# cslr_usb register map
Vendor: Texas Instruments
Peripheral module from a debugger description file (folder C5517).
Address unit: 16 bits
Registers are 16-bit, access not given, reset 0x0 unless marked. A register's access mark holds for its fields unless they carry their own. Offsets are as the file gives them; lines under a group give offsets from that group; [hi:lo] are bit positions; {n}, {i} and the like mark numbered series; 'fields as' and 'values as' point back to an identical list; <NAME> marks a mode.

## USB — USB2.0 OTG Controller
0x00 REVID1 ro reset 0x800 — Revision Identification Register 1
  [15:0] REVLSB — Lower-significant bits of the revision.
0x01 REVID2 ro reset 0x4EA1 — Revision Identification Register 2
  [15:0] REVMSB — Most-significant bits of the revision.
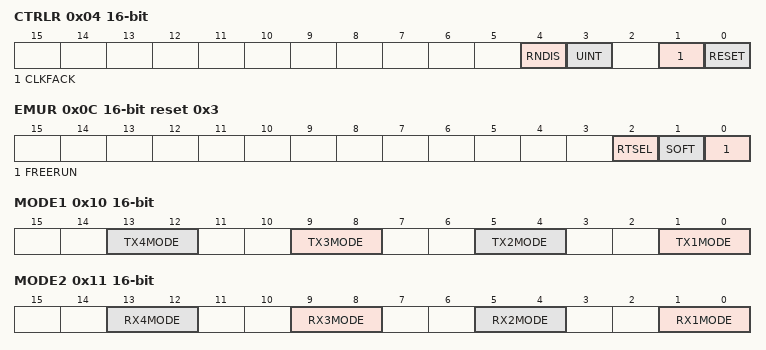
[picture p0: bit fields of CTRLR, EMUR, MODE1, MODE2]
0x04 CTRLR — Control Register
  [4] RNDIS rw — Global RNDIS mode enable for all endpoints.
    0=DISABLED (Global RNDIS mode is disabled.); 1=ENABLED (Global RNDIS mode is enabled.)
  [3] UINT rw — USB non-PDR interrupt handler enable.
    0=DISABLED (PDR interrupt handler is enabled.); 1=ENABLED (PDR interrupt handler is disabled.)
  [1] CLKFACK rw — Clock stop fast ACK enable.
    0=DISABLED (Clock stop fast ACK is disabled.); 1=ENABLED (Clock stop fast ACK is enabled.)
  [0] RESET rw — Soft reset.
    0=NONE (No effect.); 1=START (Writing a 1 starts a module reset.)
0x08 STATR — Status Register
  [0] DRVVBUS ro — Current DRVVBUS value
    0=LOGIC0 (DRVVBUS value is logic 0.); 1=LOGIC1 (DRVVBUS value is logic 1.)
0x0C EMUR reset 0x3 — Emulation Register
  [2] RTSEL rw — Real-time Enable
    0=ENABLE; 1=NOEFFECT
  [1] SOFT rw — Soft Stop Enable
    0=NOEFFECT; 1=ENABLE (Soft stop enable)
  [0] FREERUN rw — Free Run Enable
    0=NOEFFECT; 1=ENABLE (Free run enable)
0x10 MODE1 — Mode Register 1
  [4n-3:4n-4] TX{n}MODE rw (n=1..4) — Transmit endpoint {n} mode control.
    0=TRANS (Transparent mode on Transmit endpoint {n}); 1=RNDIS (RNDIS mode on Transmit endpoint {n}); 2=CDC (CDC mode on Transmit endpoint {n}); 3=GENRNDIS (Generic RNDIS mode on Transmit endpoint {n})
0x11 MODE2 — Mode Register 2
  [4n-3:4n-4] RX{n}MODE rw (n=1..4) — Receive endpoint {n} mode control
    0=TRANS (Transparent mode on Receive endpoint {n}); 1=RNDIS (RNDIS mode on Receive endpoint {n}); 2=CDC (CDC mode on Receive endpoint {n}); 3=GENRNDIS (Generic RNDIS mode on Receive endpoint {n})
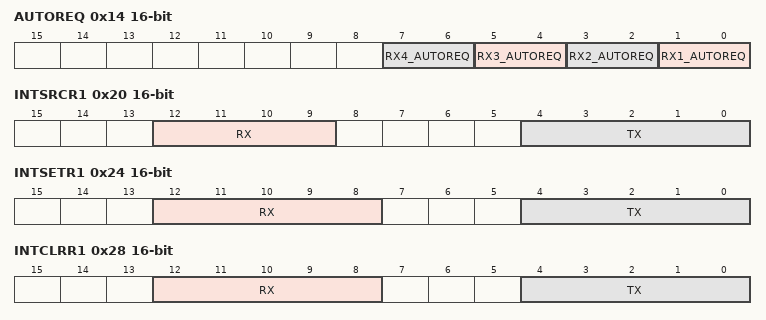
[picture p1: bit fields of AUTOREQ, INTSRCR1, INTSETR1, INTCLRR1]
0x14 AUTOREQ — Auto Request Register
  [all] fields
    0=NOAUTO (No auto request.); 1=AUTO (Auto request on all but EOP); 2=RSV (Reserved); 3=AUTOALWYS (Auto request always)
  [2n-1:2n-2] RX{n}_AUTOREQ rw (n=1..4) — Receive endpoint {n} auto request enable
0x18 SPRFIXTIME1 rw reset 0xDE80 — SRP Fix Time Register 1
  [15:0] SRPFIXTIME — SRP fix maximum time in 60 MHz cycles. Default is 700 ms (280 DE80h). Least-significant bits.
0x19 SPRFIXTIME2 rw reset 0x280 — SRP Fix Time Register 2
  [15:0] SRPFIXTIME — SRP fix maximum time in 60 MHz cycles. Default is 700 ms (280 DE80h). Most-significant bits.
0x1C TEARDOWN1 — Teardown Register 1
  [4:1] RX_TDOWN ro — RX Endpoint Teardown. Write '1' to corresponding bit to set. Read as '0'.
    0=DISABLE; 1=ENABLE
0x1D TEARDOWN2 — Teardown Register 2
  [4:1] TX_TDOWN ro — TX Endpoint Teardown. Write '1' to corresponding bit to set. Read as '0'.
    0=DISABLE; 1=ENABLE
0x20 INTSRCR1 — USB Interrupt Source Register 1
  [12:9] RX ro — RX endpoint interrupt sources Generated by the USB core (not the DMA)
  [4:0] TX ro — TX endpoint interrupt sources Generated by the USB core (not the DMA)
0x21 INTSRCR2 — USB Interrupt Source Register 2
  [8:0] USB ro — USB interrupt sources Generated by the USB core (not the DMA)
0x24 INTSETR1 — USB Interrupt Source Set Register 1
  [12:8] RX wo — Write a 1 to set equivalent RX endpoint interrupt source Allows the USB interrupt sources to be manually triggered
  [4:0] TX wo — Write a 1 to set equivalent TX endpoint interrupt source Allows the USB interrupt sources to be manually triggered
0x25 INTSETR2 — USB Interrupt Source Set Register 2
  [8:0] USB wo — Write a 1 to set equivalent USB interrupt source Allows the USB interrupt sources to be manually triggered
0x28 INTCLRR1 — USB Interrupt Source Clear Register 1
  [12:8] RX wo — Write a 1 to clear equivalent RX endpoint interrupt source Allows the CPU to acknowledge an interrupt source and turn it off
  [4:0] TX wo — Write a 1 to clear equivalent TX endpoint interrupt source Allows the CPU to acknowledge an interrupt source and turn it off
0x29 INTCLRR2 — USB Interrupt Source Clear Register 2
  [8:0] USB wo — Write a 1 to clear equivalent USB interrupt source Allows the CPU to acknowledge an interrupt source and turn it off
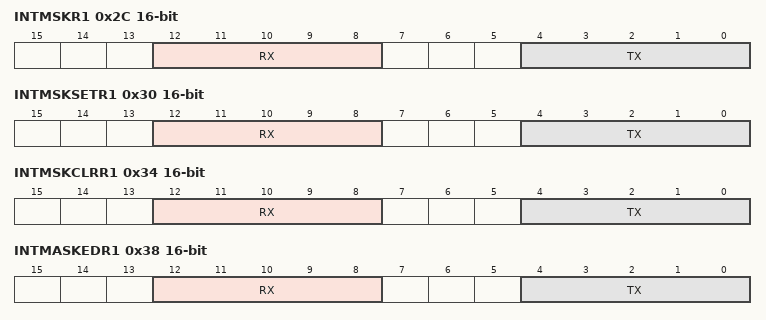
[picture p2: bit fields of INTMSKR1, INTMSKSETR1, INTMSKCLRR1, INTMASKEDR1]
0x2C INTMSKR1 — USB Interrupt Mask Register 1
  [12:8] RX ro — RX endpoint interrupt source masks Contains the masks of the interrupt sources generated by the USB core (not the DMA). These masks are used to enable or disable interrupt sources appearing as masked interrupts
  [4:0] TX ro — TX endpoint interrupt source masks Contains the masks of the interrupt sources generated by the USB core (not the DMA). These masks are used to enable or disable interrupt sources appearing as masked interrupts
0x2D INTMSKR2 — USB Interrupt Mask Register 2
  [8:0] USB ro — USB interrupt source masks Contains the masks of the interrupt sources generated by the USB core (not the DMA). These masks are used to enable or disable interrupt sources appearing as masked interrupts
0x30 INTMSKSETR1 — USB Interrupt Mask Set Register 1
  [12:8] RX wo — Write a 1 to set equivalent RX endpoint interrupt mask Allows the USB interrupt masks to be individually enabled
  [4:0] TX wo — Write a 1 to set equivalent TX endpoint interrupt mask Allows the USB interrupt masks to be individually enabled
0x31 INTMSKSETR2 — USB Interrupt Mask Set Register 2
  [8:0] USB wo — Write a 1 to set equivalent USB interrupt mask Allows the USB interrupt masks to be individually enabled
0x34 INTMSKCLRR1 — USB Interrupt Mask Clear Register 1
  [12:8] RX wo — Write a 1 to clear equivalent RX endpoint interrupt mask Allows the USB interrupt masks to be individually disabled
  [4:0] TX wo — Write a 1 to clear equivalent TX endpoint interrupt mask Allows the USB interrupt masks to be individually disabled
0x35 INTMSKCLRR2 — USB Interrupt Mask Clear Register 2
  [8:0] USB wo — Write a 1 to clear equivalent USB interrupt mask Allows the USB interrupt masks to be individually disabled
0x38 INTMASKEDR1 — USB Interrupt Source Masked Register 1
  [12:8] RX ro — RX endpoint interrupt sources masked Contains the status of the interrupt sources generated by the USB core masked by the USB Interrupt Mask Register values
  [4:0] TX ro — TX endpoint interrupt sources masked Contains the status of the interrupt sources generated by the USB core masked by the USB Interrupt Mask Register values
0x39 INTMASKEDR2 — USB Interrupt Source Masked Register 2
  [8:0] USB ro — USB interrupt sources masked Contains the status of the interrupt sources generated by the USB core masked by the USB Interrupt Mask Register values
0x3C EOIR — USB End of Interrupt Register
  [7:0] EOI_VECTOR rw
0x40 INTVECTR1 ro — USB Interrupt Vector Register 1
  [15:0] VECTOR — Input Interrupt Vector. Least significant bits.
0x41 INTVECTR2 ro — USB Interrupt Vector Register 2
  [15:0] VECTOR — Input Interrupt Vector. Most-significant bits.
{0x4C+4i} GREP{i}SZR1 ro (i=1..4) — Generic RNDIS EP{i} Size Register 1
  [15:0] SIZE — Generic RNDIS packet size. Least-significant bits.
{0x4D+4i} GREP{i}SZR2 (i=1..4) — Generic RNDIS EP{i} Size Register 2
  [0] SIZE ro — Generic RNDIS packet size. Most-significant bit.
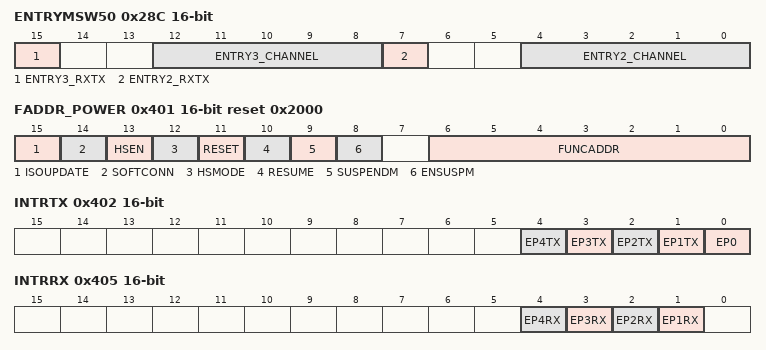
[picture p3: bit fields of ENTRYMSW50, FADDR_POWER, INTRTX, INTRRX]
0x28C ENTRYMSW50 — CDMA Scheduler Table Word Register MSW
  [15] ENTRY3_RXTX wo — This entry is for a transmit or a receive channel.
    0=XMTCH (Transmit channel); 1=RCVCH (Receive channel)
  [12:8] ENTRY3_CHANNEL wo — Indicates the channel number that is to be given an opportunity to transfer data. If this is a transmit entry, the DMA will be presented with a scheduling credit for that exact transmit channel. If this is a receive entry, the DMA will be presented with a scheduling credit for the receive FIFO that is associated with this channel. For receive FIFOs which carry traffic for more than one receive DMA channel, the exact channel number that is given in the receive credit will actually be the channel number which is currently on the head element of that Rx FIFO, which is not necessarily the channel number given in the scheduler table entry.
  [7] ENTRY2_RXTX wo — This entry is for a transmit or a receive channel.
    0=XMTCH (Transmit channel); 1=RCVCH (Receive channel)
  [4:0] ENTRY2_CHANNEL wo — Indicates the channel number that is to be given an opportunity to transfer data. If this is a transmit entry, the DMA will be presented with a scheduling credit for that exact transmit channel. If this is a receive entry, the DMA will be presented with a scheduling credit for the receive FIFO that is associated with this channel. For receive FIFOs which carry traffic for more than one receive DMA channel, the exact channel number that is given in the receive credit will actually be the channel number which is currently on the head element of that Rx FIFO, which is not necessarily the channel number given in the scheduler table entry.
0x401 FADDR_POWER reset 0x2000 — Function Address Register and Power Management Register
  [15] ISOUPDATE rw — When set, the USB controller will wait for an SOF token from the time TxPktRdy is set before sending the packet. If an IN token is received before an SOF token, then a zero length data packet will be sent Note: Only valid in Peripheral Mode. Also, this bi
  [14] SOFTCONN rw — If Soft Connect/Disconnect feature is enabled, then the USB D+/D- lines are enabled when this bit is set and tri-stated when this bit is cleared Note: Only valid in Peripheral Mode
  [13] HSEN rw — When set, the USB controller will negotiate for High-speed mode when the device is reset by the hub. If not set, the device will only operate in Full-speed mode
  [12] HSMODE ro — This bit is set when the USB contoller has successfully negotiated for High-speed mode
  [11] RESET rw — This bit is set when Reset signaling is present on the bus Note: This bit is Read/Write in Host Mode but Read-Only in Peripheral Mode
  [10] RESUME rw — Set to generate Resume signaling when the controller is in Suspend mode. The bit should be cleared after 10 ms (a maximum of 15 ms) to end Resume signaling. In Host mode, this bit is also automatically set when Resume signaling from the target is detected
  [9] SUSPENDM rw — In Host mode, this bit should be set to enter Suspend mode. In Peripheral mode, this bit is set on entry into Suspend mode. It is cleared when the interrupt register is read, or the RESUME bit is set
  [8] ENSUSPM rw — Set to enable the SUSPENDM output
  [6:0] FUNCADDR rw — 7_bit address of the peripheral part of the transaction. When used in Peripheral mode, this register should be written with the address received through a SET_ADDRESS command, which will then be used for decoding the function address in subsequent token packets. When used in Host mode, this register should be set to the value sent in a SET_ADDRESS command during device enumeration as the address for the peripheral device.
0x402 INTRTX — Interrupt Register for Endpoint 0 Plus Transmit Endpoints 1 to 4
  [n] EP{n}TX ro (n=1..4) — Tx Endpoint {n} interrupt active
  [0] EP0 ro — Endpoint 0 interrupt active
0x405 INTRRX — Interrupt Register for Receive Endpoints 1 to 4
  [n] EP{n}RX ro (n=1..4) — Rx Endpoint {n} interrupt active
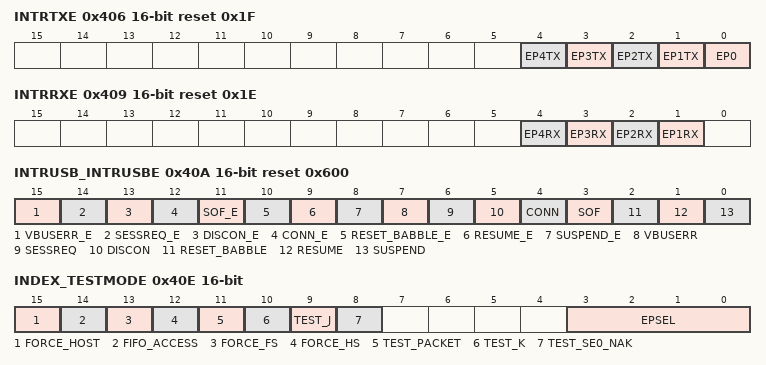
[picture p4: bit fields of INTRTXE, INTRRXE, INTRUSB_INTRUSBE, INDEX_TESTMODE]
0x406 INTRTXE reset 0x1F — Interrupt Enable Register for INTRTX
  [n] EP{n}TX rw (n=1..4) — Tx Endpoint {n} interrupt enable
  [0] EP0 rw — Endpoint 0 interrupt enable
0x409 INTRRXE reset 0x1E — Interrupt Enable Register for INTRRX
  [n] EP{n}RX rw (n=1..4) — Rx Endpoint {n} interrupt enable
0x40A INTRUSB_INTRUSBE access per field reset 0x600 — Interrupt Register for Common USB Interrupts and Interrupt Enable Register for INTRUSB
  [15] VBUSERR_E rw — Vbus error interrupt enable
  [14] SESSREQ_E rw — Session request interrupt enable
  [13] DISCON_E rw — Disconnect interrupt enable
  [12] CONN_E rw — Connect interrupt enable
  [11] SOF_E rw — Start of frame interrupt enable
  [10] RESET_BABBLE_E rw — Reset interrupt enable
  [9] RESUME_E rw — Resume interrupt enable
  [8] SUSPEND_E rw — Suspend interrupt enable
  [7] VBUSERR ro — Set when VBus drops below the VBus Valid threshold during a session Only valid when USB controller is A device All active interrupts will be cleared when this register is read
  [6] SESSREQ ro — Set when Session Request signaling has been detected Only valid when USB controller is A device
  [5] DISCON ro — Set in Host mode when a device disconnect is detected Set in Peripheral mode when a session ends
  [4] CONN ro — Set when a device connection is detected Only valid in Host mode
  [3] SOF ro — Set when a new frame starts
  [2] RESET_BABBLE ro — Set in Peripheral mode when Reset signaling is detected on the bus Set in Host mode when babble is detected
  [1] RESUME ro — Set when Resume signaling is detected on the bus while the USB controller is in Suspend mode
  [0] SUSPEND ro — Set when Suspend signaling is detected on the bus Only valid in Peripheral mode
0x40D FRAME — Frame Number Register
  [10:0] FRAMENUMBER ro — Last received frame number
0x40E INDEX_TESTMODE — Index Register for Selecting the Endpoint Status and Control Registers and Register to Enable the USB 2.0 Test Modes
  [15] FORCE_HOST rw — Set this bit to forcibly put the USB controller into Host mode when SESSION bit is set, regardless of whether it is connected to any peripheral. The controller remains in Host mode until the Session bit is cleared, even if a device is disconnected. And if the FORCE_HOST but remains set, it will re-enter Host mode next time the SESSION bit is set. The operating speed is determined using the FORCE_HS and FORCE_FS bits
  [14] FIFO_ACCESS wo — Set this bit to transfer the packet in EP0 Tx FIFO to EP0 Rx FIFO. It is cleared automatically
  [13] FORCE_FS rw — Set this bit to force the USB controller into Full-speed mode when it receives a USB reset
  [12] FORCE_HS rw — Set this bit to force the USB controller into High-speed mode when it receives a USB reset
  [11] TEST_PACKET rw — Set this bit to enter the Test_Packet test mode. In this mode, the USB controller repetitively transmits on the bus a 53-byte test packet, the form of which is defined in the Universal Serial Bus Specification Revision 2.0 Note: The test packet has a fixed format and must be loaded into the Endpoint 0 FIFO before the test mode is entered
  [10] TEST_K rw — Set this bit to enter the Test_K test mode. In this mode, the USB controller transmits a continuous K on the bus
  [9] TEST_J rw — Set this bit to enter the Test_J test mode. In this mode, the USB controller transmits a continuous J on the bus
  [8] TEST_SE0_NAK rw — Set this bit to enter the Test_SE0_NAK test mode. In this mode, the USB controller remains in High-speed mode but responds to any valid IN token with a NAK
  [3:0] EPSEL rw — Each Tx endpoint and each Rx endpoint have their own set of control/status registers. EPSEL determines which endpoint control/status registers are accessed Before accessing an endpoint s control/status registers, the endpoint number should be written to the Index register to ensure that the correct control/status registers appear in the memory map
0x411 TXMAXP_INDX — Maximum packet size for peripheral/host Tx endpoint (Index register set to select Endpoints 1 - 4 only)
  [10:0] MAXPAYLOAD rw — The maximum payload transmitted in a single transaction The value set can be up to 1024 bytes but is subject to the constraints placed by the USB Specification on packet sizes for Bulk, Interrupt and Isochronous transfers in Full-speed and High-speed operations The value written to this register should match the wMaxPacketSize field of the Standard Endpoint Descriptor for the associated endpoint. A mismatch could cause unexpected results
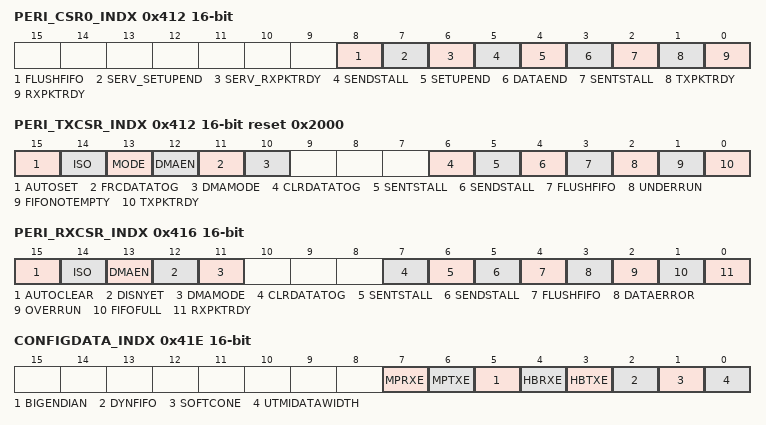
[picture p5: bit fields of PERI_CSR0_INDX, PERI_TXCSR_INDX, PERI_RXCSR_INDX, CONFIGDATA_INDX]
0x412 PERI_CSR0_INDX — Control Status register for Endpoint 0 in Peripheral mode. (Index register set to select Endpoint 0)
  [8] FLUSHFIFO wo — Set this bit to flush the next packet to be transmitted/read from the Endpoint 0 FIFO. The FIFO pointer is reset and the TXPKTRDY/RXPKTRDY bit (below) is cleared Note: FLUSHFIFO has no effect unless TXPKTRDY/RXPKTRDY is set
  [7] SERV_SETUPEND wo — Set this bit to clear the SETUPEND bit. It is cleared automatically
  [6] SERV_RXPKTRDY wo — Set this bit to clear the RXPKTRDY bit. It is cleared automatically
  [5] SENDSTALL wo — Set this bit to terminate the current transaction. The STALL handshake will be transmitted and then this bit will be cleared automatically
  [4] SETUPEND ro — This bit will be set when a control transaction ends before the DATAEND bit has been set. An interrupt will be generated and the FIFO flushed at this time. The bit is cleared by the user writing a 1 to the SERV_SETUPEND bit
  [3] DATAEND wo — Set this bit 1. When setting TXPKTRDY for the last data packet 2. When clearing RXPKTRDY after unloading the last data packet 3. When setting TXPKTRDY for a zero length data packet It is cleared automatically
  [2] SENTSTALL rw — This bit is set when a STALL handshake is transmitted. This bit should be cleared by the user
  [1] TXPKTRDY rw — Set this bit after loading a data packet into the FIFO. It is cleared automatically when the data packet has been transmitted. An interrupt is generated (if enabled) when the bit is cleared
  [0] RXPKTRDY ro — This bit is set when a data packet has been received. An interrupt is generated when this bit is set. This bit is cleared by setting the SERV_RXPKTRDY bit
0x412 PERI_TXCSR_INDX reset 0x2000 — Control Status register for peripheral Tx endpoint. (Index register set to select Endpoints 1 4)
  [15] AUTOSET rw — When this bit is set, TXPKTRDY will be automatically set when data of the maximum packet size (value in TXMAXP is loaded into the Tx FIFO. If a packet of less than the maximum packet size is loaded, then TXPKTRDY will have to be set manually. TXPKTRDY will also be automatically set when the first of two packets in the Tx FIFO has been sent and the second packet is the maximum packet size
  [14] ISO rw — Set this bit to enable the Tx endpoint for Isochronous transfers, and clear it to enable the Tx endpoint for Bulk or Interrupt transfers
  [13] MODE rw — Set this bit to enable the endpoint direction as Tx, and clear the bit to enable it as Rx Note: This bit only has any effect where the same endpoint FIFO is used for both Tx and Rx transactions
  [12] DMAEN rw — Set this bit to enable the DMA request for the Tx endpoint
  [11] FRCDATATOG rw — Set this bit to force the endpoint data toggle to switch and the data packet to be cleared from the FIFO, regardless of whether an ACK was received. This can be used by Interrupt Tx endpoints that are used to communicate rate feedback for Isochronous endpoints
  [10] DMAMODE rw — This bit should always be 0
  [6] CLRDATATOG wo — Write a 1 to this bit to reset the endpoint data toggle to 0
  [5] SENTSTALL rw — This bit is set automatically when a STALL handshake is transmitted. The FIFO is flushed and the TXPKTRDY bit is cleared (see below). The user should clear this bit
  [4] SENDSTALL rw — Write a 1 to this bit to issue a STALL handshake to an IN token. Clear this bit to terminate the stall condition Note: This bit has no effect where the endpoint is being used for Isochronous transfers
  [3] FLUSHFIFO wo — Write a 1 to this bit to flush the next packet to be transmitted from the endpoint Tx FIFO. The FIFO pointer is reset and the TXPKTRDY bit (below) is cleared. Note: FlushFIFO has no effect unless TXPKTRDY is set. Also note that, if the FIFO is double-buffered, FlushFIFO may need to be set twice to completely clear the FIFO
  [2] UNDERRUN rw — This bit is set automatically if an IN token is received when TXPKTRDY is not set. The user should clear this bit
  [1] FIFONOTEMPTY rw — This bit is set when there is at least 1 packet in the Tx FIFO. The user should clear this bit
  [0] TXPKTRDY rw — Set this bit after loading a data packet into the FIFO. It is cleared automatically when a data packet has been transmitted. An interrupt is generated (if enabled) when the bit is cleared
0x415 RXMAXP_INDX — Maximum packet size for peripheral/host Rx endpoint (Index register set to select Endpoints 1 - 4 only)
  [10:0] MAXPAYLOAD rw — Defines the maximum amount of data that can be transferred through the selected Rx endpoint in a single frame / microframe (High-speed transfers) The value set can be up to 1024 bytes but is subject to the constraints placed by the USB Specification on packet sizes for Bulk, Interrupt and Isochronous transfers in Full-speed and High-speed operations The value written to this register should match the wMaxPacketSize field of the Standard Endpoint Descriptor for the associated endpoint. A mismatch could cause unexpected results
0x416 PERI_RXCSR_INDX — Control Status register for peripheral Rx endpoint. (Index register set to select Endpoints 1 4)
  [15] AUTOCLEAR rw — When this bit is set, the RXPKTRDY bit will be automatically cleared when a packet of RXMAXP bytes has been unloaded from the Rx FIFO. When packets of less than the maximum packet size are unloaded, RXPKTRDY will have to be cleared manually
  [14] ISO rw — Set this bit to enable the Rx endpoint for Isochronous transfers, and clear it to enable the Rx endpoint for Bulk/Interrupt transfers
  [13] DMAEN rw — Set this bit to enable the DMA request for the Rx endpoints
  [12] DISNYET rw — Set this bit to disable the sending of NYET handshakes. When set, all successfully received Rx packets are ACK'd including at the point at which the FIFO becomes full Note: This bit only has any effect in High-speed mode, in which mode it should be set for all Interrupt endpoints
  [11] DMAMODE rw — This bit should always be 0
  [7] CLRDATATOG wo — Write a 1 to this bit to reset the endpoint data toggle to 0
  [6] SENTSTALL rw — This bit is set when a STALL handshake is transmitted. The FIFO is flushed and the TXPKTRDY bit is cleared (see below). The user should clear this bit
  [5] SENDSTALL rw — Write a 1 to this bit to issue a STALL handshake Clear this bit to terminate the stall condition Note: This bit has no effect where the endpoint is being used for Isochronous transfers
  [4] FLUSHFIFO wo — Write a 1 to this bit to flush the next packet to be read from the endpoint Rx FIFO. The FIFO pointer is reset and the RXPKTRDY bit (below) is cleared Note: FLUSHFIFO has no effect unless RXPKTRDY is set. Also note that, if the FIFO is double-buffered, FLUSHFIFO may need to be set twice to completely clear the FIFO
  [3] DATAERROR ro — This bit is set when RXPKTRDY is set if the data packet has a CRC or bit-stuff error. It is cleared when RXPKTRDY is cleared Note: This bit is only valid when the endpoint is operating in ISO mode. In Bulk mode, it always returns zero.
  [2] OVERRUN rw — This bit is set if an OUT packet cannot be loaded into the Rx FIFO. The user should clear this bit Note: This bit is only valid when the endpoint is operating in ISO mode. In Bulk mode, it always returns zero
  [1] FIFOFULL ro — This bit is set when no more packets can be loaded into the Rx FIFO
  [0] RXPKTRDY rw — This bit is set when a data packet has been received. The user should clear this bit when the packet has been unloaded from the Rx FIFO. An interrupt is generated when the bit is set
0x419 COUNT0_INDX — Number of received bytes in Endpoint 0 FIFO. (Index register set to select Endpoint 0)
  [6:0] EP0RXCOUNT ro — Indicates the number of received data bytes in the Endpoint 0 FIFO The value returned changes as the contents of the FIFO change and is only valid while RXPKTRDY of PERI_CSR0 or HOST_CSR0 is set
0x419 RXCOUNT_INDX — Number of bytes in host Rx endpoint FIFO. (Index register set to select Endpoints 1 - 4)
  [12:0] EPRXCOUNT ro — Holds the number of received data bytes in the packet in the Rx FIFO The value returned changes as the contents of the FIFO change and is only valid while RXPKTRDY of PERI_RXCSR or HOST_RXCSR is set
0x41E CONFIGDATA_INDX — Returns details of core configuration (Index register set to select Endpoint 0)
  [7] MPRXE — Indicates automatic amalgamation of bulk packets. (access N)
    0=NOAUTO (Automatic amalgamation of bulk packets is not selected.); 1=AUTO (Automatic amalgamation of bulk packets is selected.)
  [6] MPTXE ro — Indicates automatic splitting of bulk packets.
    0=NOAUTO (Automatic splitting of bulk packets is not selected.); 1=AUTO (Automatic splitting of bulk packets is selected.)
  [5] BIGENDIAN ro — Indicates endian ordering.
    0=LITTLE (Little-endian ordering is selected.); 1=BIG (Big-endian ordering is selected.)
  [4] HBRXE ro — Indicates high-bandwidth Rx ISO endpoint support.
    0=NOHIGHBW (High-bandwidth Rx ISO endpoint support is not selected.); 1=HIGHBW (High-bandwidth Rx ISO endpoint support is selected.)
  [3] HBTXE ro — Indicates high-bandwidth Tx ISO endpoint support.
    0=NOHIGHBW (High-bandwidth Tx ISO endpoint support is not selected.); 1=HIGHBW (High-bandwidth Tx ISO endpoint support is Selected.)
  [2] DYNFIFO ro — Indicates dynamic FIFO sizing.
    0=NODYMFIFO (Dynamic FIFO sizing option is not selected.); 1=DYMFIFO (Dynamic FIFO sizing option is selected.)
  [1] SOFTCONE ro — Indicates soft connect/disconnect.
    0=NOSFTCON (Soft connect/disconnect option is not selected); 1=SFTCON (Soft connect/disconnect option is selected)
  [0] UTMIDATAWIDTH ro — Indicates selected UTMI data width.
    0=EIGHT (8 bits); 1=SIXTEEN (16 bits)
{0x421+4i} FIFO{i}R1 rw (i=0..4) — Transmit and Receive FIFO Register 1 for Endpoint {i}
  [15:0] DATA — Writing to these addresses loads data into the Transmit FIFO for the corresponding endpoint. Reading from these addresses unloads data from the Receive FIFO for the corresponding endpoint. Least-significant bits.
{0x422+4i} FIFO{i}R2 rw (i=0..4) — Transmit and Receive FIFO Register 2 for Endpoint {i}
  [15:0] DATA — Writing to these addresses loads data into the Transmit FIFO for the corresponding endpoint. Reading from these addresses unloads data from the Receive FIFO for the corresponding endpoint. Most-significant bits.
0x461 DEVCTL — OTG Device Control Register
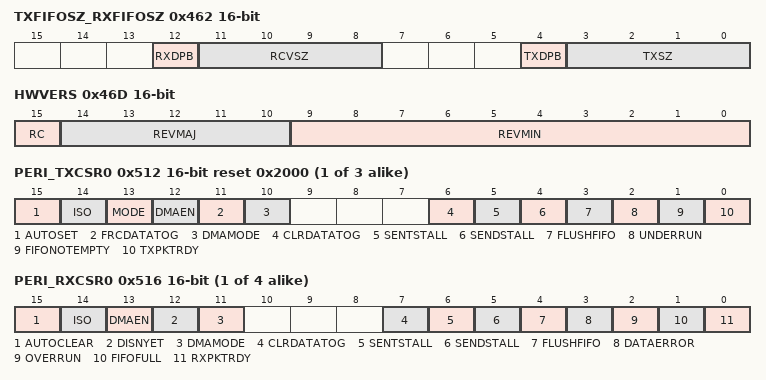
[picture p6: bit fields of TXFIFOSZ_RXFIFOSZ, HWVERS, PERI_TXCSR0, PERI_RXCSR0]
0x462 TXFIFOSZ_RXFIFOSZ — Tx RX Endpoint FIFO Size(Index register set to select Endpoints 1 - 4 only)
  [12] RXDPB rw — Double packet buffering enable
    0=SINGLE (Single packet buffering is supported); 1=DOUBLE (Double packet buffering is enabled)
  [11:8] RCVSZ ro — Maximum packet size to be allowed(before any splitting within the FIFO of Bulk packets prior to transmission) If m = SZ[3:0], the FIFO size is calculated as 2(m+3) for single packet buffering and 2(m+4) for dual packet buffering
  [4] TXDPB rw — Double packet buffering enable
    values as RXDPB
  [3:0] TXSZ ro — Maximum packet size to be allowed(before any splitting within the FIFO of Bulk packets prior to transmission) If m = SZ[3:0], the FIFO size is calculated as 2(m+3) for single packet buffering and 2(m+4) for dual packet buffering
0x465 TXFIFOADDR — Tx Endpoint FIFO Address(Index register set to select Endpoints 1 - 4 only)
  [12:0] ADDR rw — Start Address of endpoint FIFO in units of 8 bytes If m = ADDR[12:0] then the start address is 8*m
0x466 RXFIFOADDR — Rx Endpoint FIFO Address(Index register set to select Endpoints 1 - 4 only)
  fields as TXFIFOADDR
0x46D HWVERS — The hardware version register (HWVERS) contains the RTL major and minor version numbers for the USB 2.0 OTG controller module. The RTL version number is REVMAJ.REVMIN.
  [15] RC — Set to 1 if RTL is used from a Release Candidate, rather than from a full release of the core. (access N)
  [14:10] REVMAJ ro — Major version of RTL. Range is 0-31.
  [9:0] REVMIN ro — Minor version of RTL. Range is 0-999.
{0x511+0x10*i} TXMAXP{i} (i=0..2) — Maximum packet size for peripheral/host Tx endpoint
  fields as TXMAXP_INDX
{0x512+0x10*i} PERI_TXCSR{i} reset 0x2000 (i=0..2) — Control Status register for peripheral Tx endpoint. (Index register set to select Endpoints 1 4)
  fields as PERI_TXCSR_INDX
{0x515+0x10*i} RXMAXP{i} (i=0..3) — Maximum packet size for peripheral/host Rx endpoint
  fields as RXMAXP_INDX
{0x516+0x10*i} PERI_RXCSR{i} (i=0..3) — Control Status register for peripheral Rx endpoint.
  fields as PERI_RXCSR_INDX
{0x519+0x10*i} RXCOUNT{i} (i=0..3) — Number of bytes in host Rx endpoint FIFO. (Index register set to select Endpoints 1 - 4)
  fields as RXCOUNT_INDX
0x1000 DMAREVID1 ro reset 0x1900 — The CDMA revision identification register (DMAREVID) contains the revision for the module.
  [15:0] REV — Revision ID of the CPPI DMA (CDMA) module. Least-significant bits.
0x1001 DMAREVID2 ro reset 0x53 — The CDMA revision identification register (DMAREVID) contains the revision for the module.
  [15:0] REV — Revision ID of the CPPI DMA (CDMA) module. Most-significant bits.
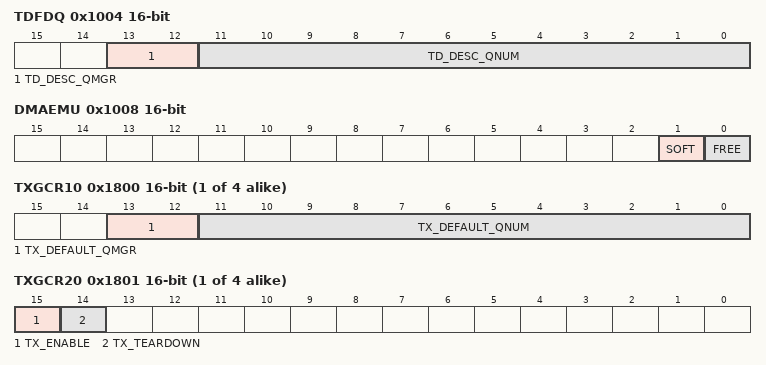
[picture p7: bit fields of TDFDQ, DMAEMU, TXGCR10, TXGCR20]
0x1004 TDFDQ — The CDMA teardown free descriptor queue control register (TDFDQ) is used to inform the DMA of the location in memory or descriptor array which is to be used for signaling of a teardown complete for each transmit and receive channel.
  [13:12] TD_DESC_QMGR rw — Controls which of the four queue managers the DMA accesses to allocate a channel teardown descriptor from the teardown descriptor queue.
  [11:0] TD_DESC_QNUM rw — Controls which of the 2K queues in the indicated queue manager should be read to allocate the channel teardown descriptors.
0x1008 DMAEMU — The CDMA emulation controls the behavior of the DMA when the emususp input is asserted.
  [1] SOFT rw, [0] FREE rw
{0x16C0+0x20*i} TXGCR{i} (i=10..13) — The Tx Channel Configuration Registers are used to initialize the behavior of each of the Tx DMA channels
  [13:12] TX_DEFAULT_QMGR wo — This field controls the default queue number within the selected queue manager number that will be used to queue teardown descriptors back to the host.
  [11:0] TX_DEFAULT_QNUM wo — This field controls the default queue number within the selected queue manager onto which teardown descriptors will be queued back to the host.
{0x1581+0x20*i} TXGCR{i} (i=20..23) — The Tx Channel Configuration Registers are used to initialize the behavior of each of the Tx DMA channels
  [15] TX_ENABLE rw — Channel control. The TX_ENABLE field is cleared after a channel teardown is complete.
    0=DISABLE (Disabled channel); 1=ENABLE (Enables channel)
  [14] TX_TEARDOWN rw — Setting this bit requests the channel to be torn down. The TX_TEARDOWN field remains set after a channel teardown is complete.
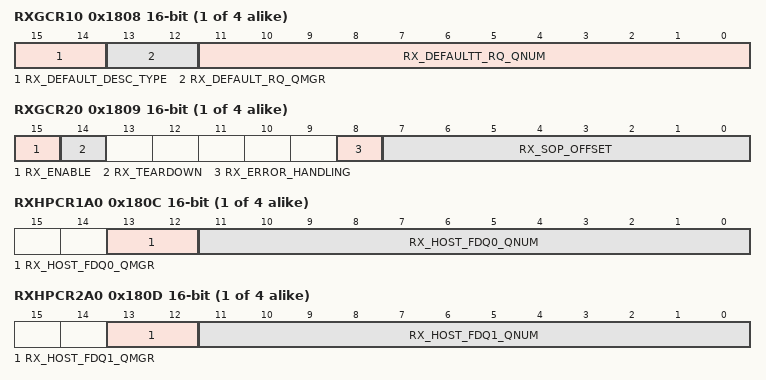
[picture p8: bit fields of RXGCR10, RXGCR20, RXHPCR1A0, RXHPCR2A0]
{0x16C8+0x20*i} RXGCR{i} (i=10..13) — The Rx Channel Configuration Registers are used to initialize the behavior of each of the Rx DMA channels
  [15:14] RX_DEFAULT_DESC_TYPE — Indicates the default descriptor type to use. The actual descriptor type that is used for reception can be overridden by information provided in the CPPI FIFO data block. (access N)
    0=RSV1 (Reserved); 1=HOST; 2=RSV2 (Reserved); 3=RSV3 (Reserved)
  [13:12] RX_DEFAULT_RQ_QMGR — Indicates the default receive queue manager that this channel should use. The actual receive queue manager index can be overridden by information provided in the CPPI FIFO data block. (access N)
  [11:0] RX_DEFAULTT_RQ_QNUM rw — Indicates the default receive queue that this channel should use. The actual receive queue that is used for reception can be overridden by information provided in the CPPI FIFO data block.
{0x1589+0x20*i} RXGCR{i} (i=20..23) — The Rx Channel Configuration Registers are used to initialize the behavior of each of the Rx DMA channels
  [15] RX_ENABLE rw — This field enables or disables the channel.
    0=DISABLE (Disables channel); 1=ENABLE (Enables channel)
  [14] RX_TEARDOWN rw — This field indicates whether or not an Rx teardown operation is complete. This field should be cleared when a channel is initialized. This field will be set after a channel teardown is complete.
  [8] RX_ERROR_HANDLING rw — Controls the error handling mode for the channel and is only used when channel errors (i.e. descriptor or buffer starvation occur):
    0=DROPPCKT (Starvation errors result in dropping packet and reclaiming any used descriptor or buffer resources back to the original queues/pools they were allocated to.); 1=RETRYPCKT (Starvation errors result in subsequent retry of the descriptor allocation operation. In this mode, the DMA will return to the IDLE state without saving its internal operational state back to the internal state RAM and without issuing an advance operation on the FIFO interface. This results in the DMA re-initiating the FIFO block transfer at a later time with the intention that additional free buffers and/or descriptors will have been added.)
  [7:0] RX_SOP_OFFSET rw — Number of bytes that are to be skipped in the SOP buffer before beginning to write the payload.
{0x180C+0x20*i} RXHPCR1A{i} (i=0..3) — The Rx Channel Host Packet Configuration Registers are used to initialize the behavior of each of the Rx DMA channels for reception of host type packets
  [13:12] RX_HOST_FDQ0_QMGR — This field specifies which Buffer Manager should be used for the 1st Rx buffer in a host type packet (access N)
  [11:0] RX_HOST_FDQ0_QNUM rw — This field specifies which Free Descriptor / Buffer Pool should be used for the 1st Rx buffer in a host type packet
{0x180D+0x20*i} RXHPCR2A{i} (i=0..3) — The Rx Channel Host Packet Configuration Registers are used to initialize the behavior of each of the Rx DMA channels for reception of host type packets
  [13:12] RX_HOST_FDQ1_QMGR — This field specifies which Buffer Manager should be used for the 2nd Rx buffer in a host type packet (access N)
  [11:0] RX_HOST_FDQ1_QNUM rw — This field specifies which Free Descriptor / Buffer Pool should be used for the 2nd Rx buffer in a host type packet
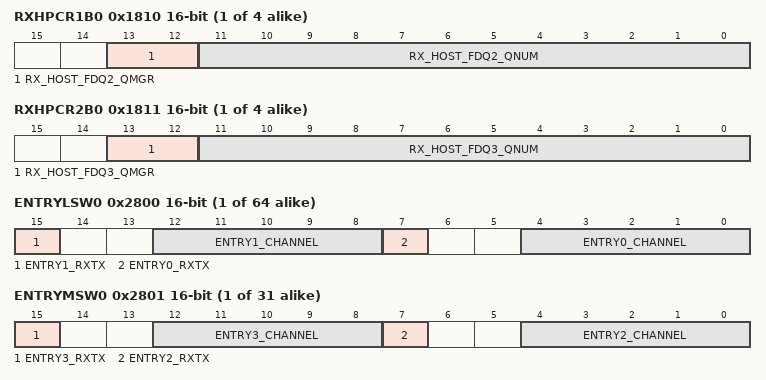
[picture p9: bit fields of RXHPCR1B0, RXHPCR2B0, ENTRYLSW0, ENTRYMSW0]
{0x1810+0x20*i} RXHPCR1B{i} (i=0..3) — The Rx Channel Host Packet Configuration Registers are used to initialize the behavior of each of the Rx DMA channels for reception of host type packets
  [13:12] RX_HOST_FDQ2_QMGR — This field specifies which Buffer Manager should be used for the 3rd Rx buffer in a host type packet (access N)
  [11:0] RX_HOST_FDQ2_QNUM rw — This field specifies which Free Descriptor / Buffer Pool should be used for the 3rd Rx buffer in a host type packet
{0x1811+0x20*i} RXHPCR2B{i} (i=0..3) — The Rx Channel Host Packet Configuration Registers are used to initialize the behavior of each of the Rx DMA channels for reception of host type packets
  [13:12] RX_HOST_FDQ3_QMGR — This field specifies which Buffer Manager should be used for the 4th Rx buffer in a host type packet (access N)
  [11:0] RX_HOST_FDQ3_QNUM rw — This field specifies which Free Descriptor / Buffer Pool should be used for the 4th Rx buffer in a host type packet
0x2000 DMA_SCHED_CTRL1 — CDMA Scheduler Control Register 1
  [7:0] LAST_ENTRY rw — Last valid entry in the scheduler table. 0 = 1 entry 1 = 2 entries & 254 = 255 entries 255 = 256 entries
0x2001 DMA_SCHED_CTRL2 — CDMA Scheduler Control Register 2
  [15] ENABLE rw — This is the enable bit for the scheduler.
    0=ENABLED (Scheduler is disabled and will no longer fetch entries from the scheduler table or pass credits to the DMA controller); 1=DISABLED (Scheduler is enabled. This bit should only be set after the table has been initialized.)
{0x2800+4i} ENTRYLSW{i} (i=0..63) — CDMA Scheduler Table Word Register LSW
  [15] ENTRY1_RXTX wo — This entry is for a transmit or a receive channel.
    0=XMTCH (Transmit channel); 1=RCVCH (Receive channel)
  [12:8] ENTRY1_CHANNEL wo — Indicates the channel number that is to be given an opportunity to transfer data. If this is a transmit entry, the DMA will be presented with a scheduling credit for that exact transmit channel. If this is a receive entry, the DMA will be presented with a scheduling credit for the receive FIFO that is associated with this channel. For receive FIFOs which carry traffic for more than one receive DMA channel, the exact channel number that is given in the receive credit will actually be the channel number which is currently on the head element of that Rx FIFO, which is not necessarily the channel number given in the scheduler table entry.
  [7] ENTRY0_RXTX wo — This entry is for a transmit or a receive channel.
    0=XMTCH (Transmit channel); 1=RCVCH (Receive channel)
  [4:0] ENTRY0_CHANNEL wo — Indicates the channel number that is to be given an opportunity to transfer data. If this is a transmit entry, the DMA will be presented with a scheduling credit for that exact transmit channel. If this is a receive entry, the DMA will be presented with a scheduling credit for the receive FIFO that is associated with this channel. For receive FIFOs which carry traffic for more than one receive DMA channel, the exact channel number that is given in the receive credit will actually be the channel number which is currently on the head element of that Rx FIFO, which is not necessarily the channel number given in the scheduler table entry.
{0x2801+4i} ENTRYMSW{i} (i=0..30) — CDMA Scheduler Table Word Register MSW
  fields as ENTRYMSW50
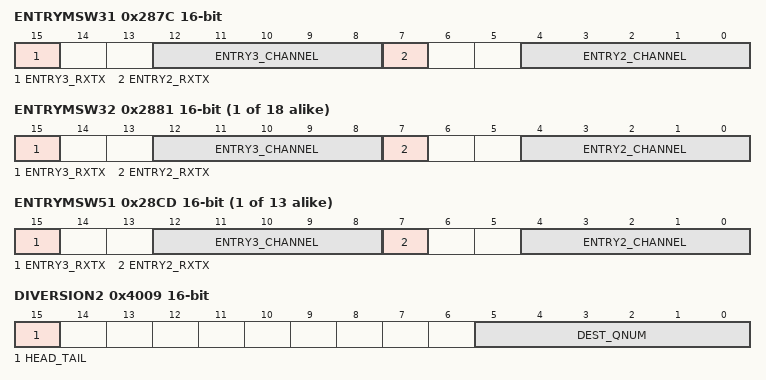
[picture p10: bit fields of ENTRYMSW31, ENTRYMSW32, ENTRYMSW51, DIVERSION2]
0x287C ENTRYMSW31 — CDMA Scheduler Table Word Register MSW
  fields as ENTRYMSW50
{0x2801+4i} ENTRYMSW{i} (i=32..49) — CDMA Scheduler Table Word Register MSW
  fields as ENTRYMSW50
{0x2801+4i} ENTRYMSW{i} (i=51..63) — CDMA Scheduler Table Word Register MSW
  fields as ENTRYMSW50
0x4000 QMGRREVID1 ro reset 0x1200 — Queue Manager Revision Identification Register 1
  [15:0] REV — Revision ID of the queue manager. Least-significant bits.
0x4001 QMGRREVID2 ro reset 0x52 — Queue Manager Revision Identification Register 2
  [15:0] REV — Revision ID of the queue manager. Most-significant bits.
0x4008 DIVERSION1 — Queue Manager Queue Diversion Register 1
  [13:0] SOURCE_QNUM wo — Source Queue Number
0x4009 DIVERSION2 — Queue Manager Queue Diversion Register 2
  [15] HEAD_TAIL wo — Indicates whether queue contents should be merged on to the head or tail of the destination queue.
    0=HEAD; 1=TAIL
  [5:0] DEST_QNUM wo — Destination Queue Number
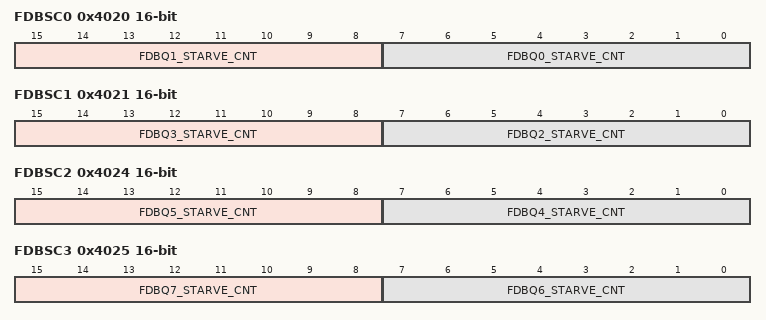
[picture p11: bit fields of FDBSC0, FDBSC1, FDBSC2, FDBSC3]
0x4020 FDBSC0 ro — Queue Manager Free Descriptor/Buffer Starvation Count Register 0
  [15:8] FDBQ1_STARVE_CNT — This field increments each time the Free Descriptor Buffer Queue 1 is read while it is empty. This field is cleared when read.
  [7:0] FDBQ0_STARVE_CNT — This field increments each time the Free Descriptor Buffer Queue 0 is read while it is empty. This field is cleared when read.
0x4021 FDBSC1 ro — Queue Manager Free Descriptor/Buffer Starvation Count Register 1
  [15:8] FDBQ3_STARVE_CNT — This field increments each time the Free Descriptor Buffer Queue 3 is read while it is empty. This field is cleared when read.
  [7:0] FDBQ2_STARVE_CNT — This field increments each time the Free Descriptor Buffer Queue 2 is read while it is empty. This field is cleared when read.
0x4024 FDBSC2 ro — Queue Manager Free Descriptor/Buffer Starvation Count Register 2
  [15:8] FDBQ5_STARVE_CNT — This field increments each time the Free Descriptor Buffer Queue 5 is read while it is empty. This field is cleared when read.
  [7:0] FDBQ4_STARVE_CNT — This field increments each time the Free Descriptor Buffer Queue 4 is read while it is empty. This field is cleared when read.
0x4025 FDBSC3 ro — Queue Manager Free Descriptor/Buffer Starvation Count Register 3
  [15:8] FDBQ7_STARVE_CNT — This field increments each time the Free Descriptor Buffer Queue 7 is read while it is empty. This field is cleared when read.
  [7:0] FDBQ6_STARVE_CNT — This field increments each time the Free Descriptor Buffer Queue 6 is read while it is empty. This field is cleared when read.
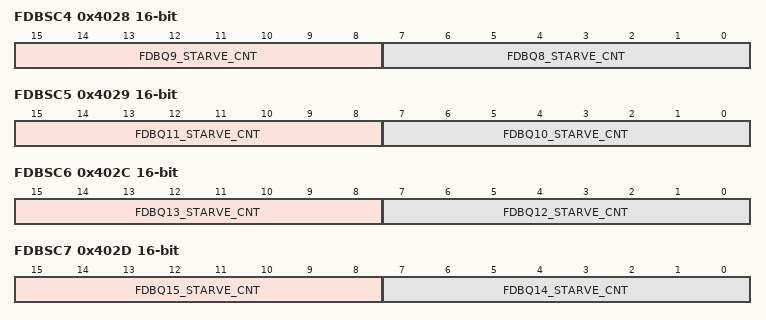
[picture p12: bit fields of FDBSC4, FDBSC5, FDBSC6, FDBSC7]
0x4028 FDBSC4 ro — Queue Manager Free Descriptor/Buffer Starvation Count Register 4
  [15:8] FDBQ9_STARVE_CNT — This field increments each time the Free Descriptor Buffer Queue 9 is read while it is empty. This field is cleared when read.
  [7:0] FDBQ8_STARVE_CNT — This field increments each time the Free Descriptor Buffer Queue 8 is read while it is empty. This field is cleared when read.
0x4029 FDBSC5 ro — Queue Manager Free Descriptor Buffer Starvation Count Register 5
  [15:8] FDBQ11_STARVE_CNT — This field increments each time the Free Descriptor Buffer Queue 11 is read while it is empty. This field is cleared when read.
  [7:0] FDBQ10_STARVE_CNT — This field increments each time the Free Descriptor Buffer Queue 10 is read while it is empty. This field is cleared when read.
0x402C FDBSC6 ro — Queue Manager Free Descriptor/Buffer Starvation Count Register 6
  [15:8] FDBQ13_STARVE_CNT — This field increments each time the Free Descriptor Buffer Queue 13 is read while it is empty. This field is cleared when read.
  [7:0] FDBQ12_STARVE_CNT — This field increments each time the Free Descriptor Buffer Queue 12 is read while it is empty. This field is cleared when read.
0x402D FDBSC7 ro — Queue Manager Free Descriptor/Buffer Starvation Count Register 7
  [15:8] FDBQ15_STARVE_CNT — This field increments each time the Free Descriptor Buffer Queue 15 is read while it is empty. This field is cleared when read.
  [7:0] FDBQ14_STARVE_CNT — This field increments each time the Free Descriptor Buffer Queue 14 is read while it is empty. This field is cleared when read.
0x4080 LRAM0BASE1 ro — Queue Manager Linking RAM Region 0 Base Address Register 1
  [15:0] REGION0_BASE — This field stores the base address for the first region of the linking RAM. This may be anywhere in 32-bit address space but would be typically located in on-chip memory. Least-significant bits.
0x4081 LRAM0BASE2 ro — Queue Manager Linking RAM Region 0 Base Address Register 2
  [15:0] REGION0_BASE — This field stores the base address for the first region of the linking RAM. This may be anywhere in 32-bit address space but would be typically located in on-chip memory. Most-significant bits.
0x4084 LRAM0SIZE — Queue Manager Linking RAM Region 0 Size Register
  [13:0] REGION0_SIZE rw — This field indicates the number of entries that are contained in the linking RAM region 0. A descriptor with index less than region0_size value has its linking location in region 0. A descriptor with index greater than region0_size has its linking location in region 1. The queue manager will add the index (left shifted by 2 bits) to the appropriate regionX_base_addr to get the absolute 32-bit address to the linking location for a descriptor.
0x4088 LRAM1BASE1 ro — Queue Manager Linking RAM Region 1 Base Address Register 1
  [15:0] REGION1_BASE — This field stores the base address for the first region of the linking RAM. This may be anywhere in 32-bit address space but would be typically located in on-chip memory. Least-significant bits.
0x4089 LRAM1BASE2 ro — Queue Manager Linking RAM Region 1 Base Address Register 2
  [15:0] REGION1_BASE — This field stores the base address for the first region of the linking RAM. This may be anywhere in 32-bit address space but would be typically located in on-chip memory. Most-significant bits.
0x4090 PEND0 ro — Queue Manager Queue Pending Register 0
  [15:0] QPEND — This field indicates the queue pending status for queues 15-0.
0x4091 PEND1 ro — Queue Manager Queue Pending Register 1
  [15:0] QPEND — This field indicates the queue pending status for queues 31-16.
0x4094 PEND2 ro — Queue Manager Queue Pending Register 2
  [15:0] QPEND — This field indicates the queue pending status for queues 47-32.
0x4095 PEND3 ro — Queue Manager Queue Pending Register 3
  [15:0] QPEND — This field indicates the queue pending status for queues 63:48.
0x4098 PEND4 ro — Queue Manager Queue Pending Register 4
  [15:0] QPEND — This field indicates the queue pending status for queues 79-64.
0x4099 PEND5 ro — Queue Manager Queue Pending Register 5
  [15:0] QPEND — This field indicates the queue pending status for queues 95-80.
{0x4F60+0x10*i} QMEMRBASE{i} rw (i=10..19) — Queue Manager Memory Region R Base Address Register 1
  [15:0] REG — This field contains the base address of the memory region R. Least-significant bits.
{0x4EC1+0x10*i} QMEMRBASE{i} rw (i=20..29) — Queue Manager Memory Region R Base Address Register 2
  [15:0] REG — This field contains the base address of the memory region R. Most-significant bits.
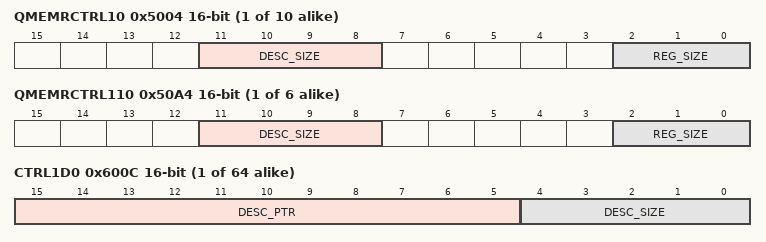
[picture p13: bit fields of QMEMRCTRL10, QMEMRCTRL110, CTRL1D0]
{0x4F64+0x10*i} QMEMRCTRL{i} (i=10..19) — Queue Manager Memory Region R Control Register 1
  [11:8] DESC_SIZE rw — This field indicates the size of each descriptor in this memory region. It is an encoded value that specifies descriptor size as 2^(5+desc_size) number of bytes. The settings of desc_size from 9-15 are reserved.
  [2:0] REG_SIZE rw — This field indicates the size of the memory region (in terms of number of descriptors). It is an encoded value that specifies region size as 2^(5+reg_size) number of descriptors.
    0=SIZE32 (32); 1=SIZE64 (64); 2=SIZE128 (128); 3=SIZE256 (256); 4=SIZE512 (512); 5=SIZE1K (1K); 6=SIZE2K (2K); 7=SIZE4K (4K)
{0x4EC5+0x10*i} QMEMRCTRL{i} (i=20..29) — Queue Manager Memory Region R Control Register 2
  [13:0] START_INDEX rw — This field indicates where in linking RAM does the descriptor linking information corresponding to memory region R starts.
{0x49C0+0x10*i} QMEMRBASE{i} rw (i=110..115) — Queue Manager Memory Region R Base Address Register 1
  fields as QMEMRBASE10
{0x4381+0x10*i} QMEMRBASE{i} rw (i=210..215) — Queue Manager Memory Region R Base Address Register 2
  fields as QMEMRBASE20
{0x49C4+0x10*i} QMEMRCTRL{i} (i=110..115) — Queue Manager Memory Region R Control Register 1
  fields as QMEMRCTRL10
{0x4385+0x10*i} QMEMRCTRL{i} (i=210..215) — Queue Manager Memory Region R Control Register 2
  fields as QMEMRCTRL20
{0x600C+0x10*i} CTRL1D{i} rw (i=0..63) — Queue Manager Queue N Control Register 1 D
  [15:5] DESC_PTR — Descriptor pointer. It will be read as zero if the queue is empty. It will indicate a 32-bit aligned address that points to a descriptor when the queue is not empty. Least-significant bits.
  [4:0] DESC_SIZE — Descriptor Size. It is encoded in 4-byte increments with values 0 to 31 representing 24 and so on to 148 bytes. This field will return a 0x0 when an empty queue is read.
{0x600D+0x10*i} CTRL2D{i} rw (i=0..63) — Queue Manager Queue N Control Register 2 D
  [15:0] DESC_PTR — Descriptor pointer. It will be read as zero if the queue is empty. It will indicate a 32-bit aligned address that points to a descriptor when the queue is not empty. Most-significant bits.
{0x6800+0x10*i} QSTATA{i} (i=0..53) — Queue Manager Queue N Status Register A
  [13:0] QUEUE_ENTRY_COUNT ro — This field indicates how many packets are currently queued on the queue.
{0x6804+0x10*i} QSTAT1B{i} ro (i=0..63) — Queue Manager Queue N Status Register 1 B
  [15:0] QUEUE_BYTE_COUNT — This field indicates how many bytes total are contained in all of the packets which are currently queued on this queue. Least-significant bits.
{0x6805+0x10*i} QSTAT2B{i} (i=0..63) — Queue Manager Queue N Status Register 2 B
  [11:0] QUEUE_BYTE_COUNT ro — This field indicates how many bytes total are contained in all of the packets which are currently queued on this queue. Most-significant bits.
{0x6808+0x10*i} QSTAT1C{i} (i=0..63) — Queue Manager Queue N Status Register 1 C
  [13:0] PACKET_SIZE ro — This field indicates packet size and is assumed to be zero on each packet add unless the value is explicitly overwritten. This field indicates packet size for packet pop operation.
{0x6800+0x10*i} QSTATA{i} (i=55..63) — Queue Manager Queue N Status Register A
  fields as QSTATA0
0x6D60 QSTATA54 — Queue Manager Queue N Status Register A
  fields as QSTATA0
